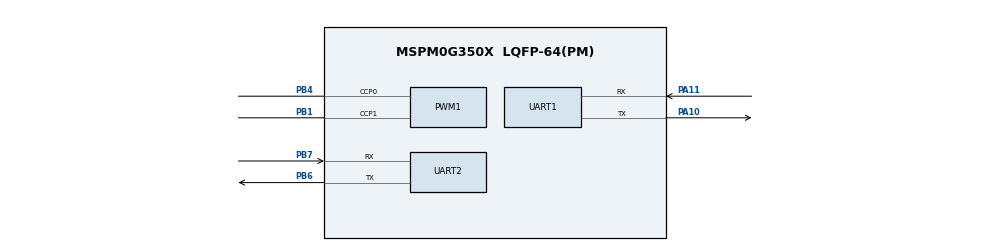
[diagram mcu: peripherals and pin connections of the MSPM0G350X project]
/**
 * @cliArgs --device "MSPM0G350X" --part "Default" --package "LQFP-64(PM)" --product "mspm0_sdk@2.05.00.05"
 * @versions {"tool":"1.21.0+3721"}
 */

/**
 * Import the modules used in this configuration.
 */
const ADC12   = scripting.addModule("/ti/driverlib/ADC12", {}, false);
const ADC121  = ADC12.addInstance();
const GPIO    = scripting.addModule("/ti/driverlib/GPIO", {}, false);
const GPIO1   = GPIO.addInstance();
const GPIO2   = GPIO.addInstance();
const GPIO3   = GPIO.addInstance();
const GPIO4   = GPIO.addInstance();
const GPIO5   = GPIO.addInstance();
const GPIO6   = GPIO.addInstance();
const GPIO7   = GPIO.addInstance();
const GPIO8   = GPIO.addInstance();
const GPIO9   = GPIO.addInstance();
const GPIO10  = GPIO.addInstance();
const GPIO11  = GPIO.addInstance();
const PWM     = scripting.addModule("/ti/driverlib/PWM", {}, false);
const PWM1    = PWM.addInstance();
const SYSCTL  = scripting.addModule("/ti/driverlib/SYSCTL");
const SYSTICK = scripting.addModule("/ti/driverlib/SYSTICK");
const TIMER   = scripting.addModule("/ti/driverlib/TIMER", {}, false);
const TIMER1  = TIMER.addInstance();
const UART    = scripting.addModule("/ti/driverlib/UART", {}, false);
const UART1   = UART.addInstance();
const UART2   = UART.addInstance();

/**
 * Write custom configuration values to the imported modules.
 */
const gate7  = system.clockTree["MFCLKGATE"];
gate7.enable = true;

ADC121.sampClkDiv                        = "DL_ADC12_CLOCK_DIVIDE_8";
ADC121.repeatMode                        = true;
ADC121.$name                             = "ADC_VOLTAGE";
ADC121.enabledInterrupts                 = ["DL_ADC12_INTERRUPT_MEM0_RESULT_LOADED"];
ADC121.sampleTime0                       = "6us";
ADC121.peripheral.$assign                = "ADC0";
ADC121.peripheral.adcPin0.$assign        = "PA27";
ADC121.adcPin0Config.hideOutputInversion = scripting.forceWrite(false);
ADC121.adcPin0Config.$name               = "ti_driverlib_gpio_GPIOPinGeneric4";

const Board = scripting.addModule("/ti/driverlib/Board", {}, false);

GPIO1.$name                              = "LED1";
GPIO1.port                               = "PORTA";
GPIO1.associatedPins[0].$name            = "PIN_0";
GPIO1.associatedPins[0].internalResistor = "PULL_DOWN";
GPIO1.associatedPins[0].assignedPin      = "0";

GPIO2.$name                         = "KEY";
GPIO2.port                          = "PORTB";
GPIO2.associatedPins[0].direction   = "INPUT";
GPIO2.associatedPins[0].polarity    = "RISE";
GPIO2.associatedPins[0].$name       = "PIN_21";
GPIO2.associatedPins[0].assignedPin = "21";

GPIO3.$name                               = "ENCODERA";
GPIO3.port                                = "PORTA";
GPIO3.associatedPins.create(2);
GPIO3.associatedPins[0].direction         = "INPUT";
GPIO3.associatedPins[0].interruptEn       = true;
GPIO3.associatedPins[0].polarity          = "RISE";
GPIO3.associatedPins[0].$name             = "E1A";
GPIO3.associatedPins[0].assignedPin       = "16";
GPIO3.associatedPins[0].interruptPriority = "0";
GPIO3.associatedPins[1].direction         = "INPUT";
GPIO3.associatedPins[1].interruptEn       = true;
GPIO3.associatedPins[1].polarity          = "RISE";
GPIO3.associatedPins[1].$name             = "E1B";
GPIO3.associatedPins[1].assignedPin       = "15";
GPIO3.associatedPins[1].interruptPriority = "0";

GPIO4.$name                   = "GPIO_GRP_0";
GPIO4.associatedPins[0].$name = "PIN_1";

GPIO5.$name                         = "AIN1";
GPIO5.port                          = "PORTA";
GPIO5.associatedPins[0].$name       = "PIN_12";
GPIO5.associatedPins[0].assignedPin = "12";

GPIO6.$name                         = "AIN2";
GPIO6.port                          = "PORTA";
GPIO6.associatedPins[0].$name       = "PIN_13";
GPIO6.associatedPins[0].assignedPin = "13";

GPIO7.$name                         = "BIN1";
GPIO7.port                          = "PORTB";
GPIO7.associatedPins[0].assignedPin = "16";
GPIO7.associatedPins[0].$name       = "Pin_Bin1";

GPIO8.$name                         = "BIN2";
GPIO8.port                          = "PORTB";
GPIO8.associatedPins[0].assignedPin = "0";
GPIO8.associatedPins[0].$name       = "Pin_Bin2";

GPIO9.$name                               = "ENCODERB";
GPIO9.port                                = "PORTA";
GPIO9.associatedPins.create(2);
GPIO9.associatedPins[0].$name             = "E2A";
GPIO9.associatedPins[0].direction         = "INPUT";
GPIO9.associatedPins[0].assignedPin       = "17";
GPIO9.associatedPins[0].interruptEn       = true;
GPIO9.associatedPins[0].polarity          = "RISE";
GPIO9.associatedPins[0].interruptPriority = "0";
GPIO9.associatedPins[1].$name             = "E2B";
GPIO9.associatedPins[1].direction         = "INPUT";
GPIO9.associatedPins[1].assignedPin       = "22";
GPIO9.associatedPins[1].interruptEn       = true;
GPIO9.associatedPins[1].polarity          = "RISE";
GPIO9.associatedPins[1].interruptPriority = "0";

GPIO10.$name                         = "GPIO_CLK";
GPIO10.port                          = "PORTB";
GPIO10.associatedPins[0].$name       = "PIN_23";
GPIO10.associatedPins[0].assignedPin = "23";

GPIO11.$name                         = "GPIO_SI";
GPIO11.port                          = "PORTA";
GPIO11.associatedPins[0].$name       = "PIN_25";
GPIO11.associatedPins[0].assignedPin = "25";

PWM1.$name                      = "PWM_0";
PWM1.timerStartTimer            = true;
PWM1.pwmMode                    = "EDGE_ALIGN_UP";
PWM1.timerCount                 = 3200;
PWM1.peripheral.ccp0Pin.$assign = "PB4";
PWM1.peripheral.ccp1Pin.$assign = "PB1";
PWM1.PWM_CHANNEL_0.$name        = "ti_driverlib_pwm_PWMTimerCC0";
PWM1.PWM_CHANNEL_1.$name        = "ti_driverlib_pwm_PWMTimerCC1";
PWM1.ccp0PinConfig.$name        = "ti_driverlib_gpio_GPIOPinGeneric2";
PWM1.ccp1PinConfig.$name        = "ti_driverlib_gpio_GPIOPinGeneric3";

SYSCTL.forceDefaultClkConfig = true;
SYSCTL.clockTreeEn           = true;

SYSTICK.periodEnable      = true;
SYSTICK.systickEnable     = true;
SYSTICK.interruptPriority = "0";
SYSTICK.period            = 32;

TIMER1.$name            = "TIMER_0";
TIMER1.timerClkDiv      = 8;
TIMER1.timerClkPrescale = 200;
TIMER1.timerStartTimer  = true;
TIMER1.timerMode        = "PERIODIC";
TIMER1.interrupts       = ["ZERO"];
TIMER1.timerPeriod      = "10 ms";

UART1.$name                    = "UART_0";
UART1.enabledInterrupts        = ["RX"];
UART1.uartClkSrc               = "MFCLK";
UART1.peripheral.$assign       = "UART0";
UART1.peripheral.rxPin.$assign = "PA11";
UART1.peripheral.txPin.$assign = "PA10";
UART1.txPinConfig.$name        = "ti_driverlib_gpio_GPIOPinGeneric0";
UART1.rxPinConfig.$name        = "ti_driverlib_gpio_GPIOPinGeneric1";

UART2.$name                    = "UART_1";
UART2.uartClkSrc               = "MFCLK";
UART2.enabledInterrupts        = ["RX"];
UART2.peripheral.rxPin.$assign = "PB7";
UART2.peripheral.txPin.$assign = "PB6";
UART2.txPinConfig.$name        = "ti_driverlib_gpio_GPIOPinGeneric5";
UART2.rxPinConfig.$name        = "ti_driverlib_gpio_GPIOPinGeneric6";

/**
 * Pinmux solution for unlocked pins/peripherals. This ensures that minor changes to the automatic solver in a future
 * version of the tool will not impact the pinmux you originally saw.  These lines can be completely deleted in order to
 * re-solve from scratch.
 */
Board.peripheral.$suggestSolution             = "DEBUGSS";
Board.peripheral.swclkPin.$suggestSolution    = "PA20";
Board.peripheral.swdioPin.$suggestSolution    = "PA19";
GPIO1.associatedPins[0].pin.$suggestSolution  = "PA0";
GPIO2.associatedPins[0].pin.$suggestSolution  = "PB21";
GPIO3.associatedPins[0].pin.$suggestSolution  = "PA16";
GPIO3.associatedPins[1].pin.$suggestSolution  = "PA15";
GPIO4.associatedPins[0].pin.$suggestSolution  = "PB13";
GPIO5.associatedPins[0].pin.$suggestSolution  = "PA12";
GPIO6.associatedPins[0].pin.$suggestSolution  = "PA13";
GPIO7.associatedPins[0].pin.$suggestSolution  = "PB16";
GPIO8.associatedPins[0].pin.$suggestSolution  = "PB0";
GPIO9.associatedPins[0].pin.$suggestSolution  = "PA17";
GPIO9.associatedPins[1].pin.$suggestSolution  = "PA22";
GPIO10.associatedPins[0].pin.$suggestSolution = "PB23";
GPIO11.associatedPins[0].pin.$suggestSolution = "PA25";
PWM1.peripheral.$suggestSolution              = "TIMA1";
TIMER1.peripheral.$suggestSolution            = "TIMA0";
UART2.peripheral.$suggestSolution             = "UART1";
